# GD32W515Px register map
File version: 1.0
CPU: CM33 r0p0, little endian, MPU, FPU, 4 interrupt priority bits
Registers are 32-bit, read-write, reset 0x0 unless marked. A register's access mark holds for its fields unless they carry their own. Offsets are from the block's base; [hi:lo] are bit positions; {n}, {i} and the like mark numbered series.

## ICACHE
Base 0x40080000
Same registers: SEC_ICACHE 0x50080000
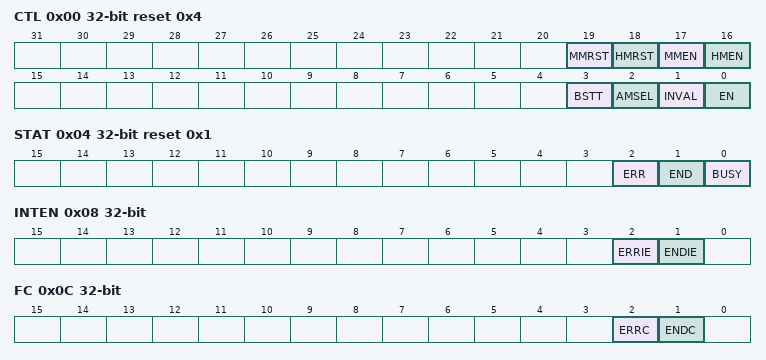
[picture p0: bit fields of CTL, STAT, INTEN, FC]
0x00 CTL reset 0x4 — Control register
  [19] MMRST — Miss monitor reset
  [18] HMRST — Hit monitor reset
  [17] MMEN — Miss monitor enable
  [16] HMEN — Hit monitor enable
  [3] BSTT — Burst type for fast bus
  [2] AMSEL — Cache set-associativity mode selection
  [1] INVAL — Cache invalidation, Set by software and cleared by hardware
  [0] EN — cache enabled
0x04 STAT ro reset 0x1 — Status register
  [2] ERR — Cache error flag
  [1] END — operation end flag
  [0] BUSY — Busy flag
0x08 INTEN — Interrupt enable register
  [2] ERRIE — cache error interrupt enable
  [1] ENDIE — cache operation end interrupt enable
0x0C FC wo — Flag clear register
  [2] ERRC — Software clear cache error flag
  [1] ENDC — Software clear operation end flag
0x10 HMC ro — Hit monitor counter register
  [31:0] HMC — Cache hit monitor counter
0x14 MMC ro — Miss monitor counter register
  [15:0] MMC — Cache miss monitor counter
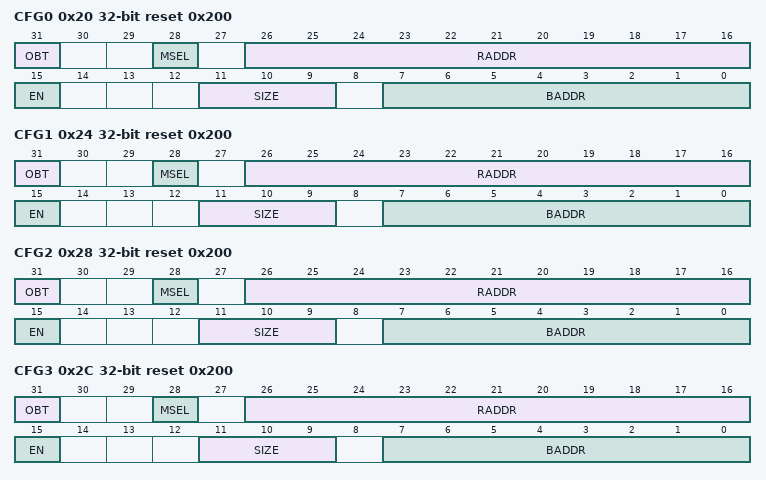
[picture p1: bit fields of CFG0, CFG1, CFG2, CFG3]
0x20 CFG0 reset 0x200 — Configuration register 0
  [31] OBT — Output burst type for region 0
  [28] MSEL — Region 0 AHB cache master selection
  [26:16] RADDR — Region 0 remapped address, this field replaces the alias address defined by BADDR field.
  [15] EN — Region 0 enable
  [11:9] SIZE — Region 0 size
  [7:0] BADDR — Region 0 base address
0x24 CFG1 reset 0x200 — Configuration register 1
  [31] OBT — Output burst type for region 1
  [28] MSEL — Region 1 AHB cache master selection
  [26:16] RADDR — Region 1 remapped address, this field replaces the alias address defined by BADDR field.
  [15] EN — Region 1 enable
  [11:9] SIZE — Region 1 size
  [7:0] BADDR — Region 1 base address
0x28 CFG2 reset 0x200 — Configuration register
  [31] OBT — Output burst type for region 2
  [28] MSEL — Region 2 AHB cache master selection
  [26:16] RADDR — Region 2 remapped address, this field replaces the alias address defined by BADDR field.
  [15] EN — Region 2 enable
  [11:9] SIZE — Region 2 size
  [7:0] BADDR — Region 2 base address
0x2C CFG3 reset 0x200 — Configuration register
  [31] OBT — Output burst type for region 3
  [28] MSEL — Region 3 AHB cache master selection
  [26:16] RADDR — Region 3 remapped address, this field replaces the alias address defined by BADDR field.
  [15] EN — Region 3 enable
  [11:9] SIZE — Region 3 size
  [7:0] BADDR — Region 3 base address

## PMU — Power management unit
Base 0x40007000
Same registers: SEC_PMU 0x50007000
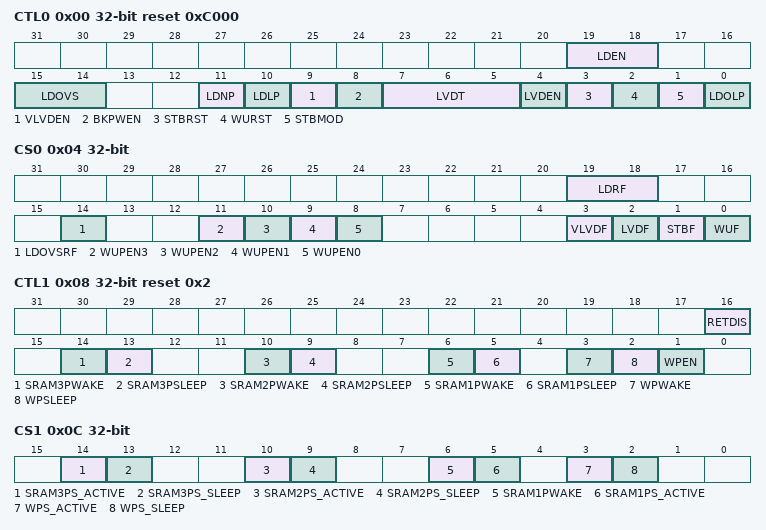
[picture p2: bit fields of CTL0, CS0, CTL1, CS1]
0x00 CTL0 reset 0xC000 — power control register 0
  [19:18] LDEN — Low-driver mode enable in Deep-sleep mode
  [15:14] LDOVS — LDO output voltage select
  [11] LDNP — Low-driver mode when use normal power LDO
  [10] LDLP — Low-driver mode when use low power LDO
  [9] VLVDEN — VDDA low voltage detect enable
  [8] BKPWEN — Backup Domain Write Enable
  [7:5] LVDT — Low Voltage Detector Threshold
  [4] LVDEN — Low Voltage Detector Enable
  [3] STBRST — Standby Flag Reset
  [2] WURST — Wakeup Flag Reset
  [1] STBMOD — Standby Mode
  [0] LDOLP — LDO Low Power Mode
0x04 CS0 access per field — power control/status register 0
  [19:18] LDRF rw — Low-driver mode ready flag
  [14] LDOVSRF ro — LDO voltage select ready flag
  [11] WUPEN3 rw — WKUP Pin3(PA12) Enable
  [10] WUPEN2 rw — WKUP Pin2(PB2) Enable
  [9] WUPEN1 rw — WKUP Pin1(PA15) Enable
  [8] WUPEN0 rw — WKUP Pin0(PA2) Enable
  [3] VLVDF ro — VDDA Low Voltage Detector Status Flag
  [2] LVDF ro — Low Voltage Detector Status Flag
  [1] STBF ro — Standby flag
  [0] WUF ro — Wakeup flag
0x08 CTL1 reset 0x2 — Control register 1
  [16] RETDIS — No retention register when WIFI por-off
  [14] SRAM3PWAKE — SRAM3 wakeup by software
  [13] SRAM3PSLEEP — SRAM3 go to sleep by software
  [10] SRAM2PWAKE — SRAM2 wakeup by software
  [9] SRAM2PSLEEP — SRAM2 go to sleep by software
  [6] SRAM1PWAKE — SRAM1 wakeup by software
  [5] SRAM1PSLEEP — SRAM1 go to sleep by software
  [3] WPWAKE — WIFI wakeup
  [2] WPSLEEP — WIFI go to sleep by software only when WPEN bit is 1
  [1] WPEN — WIFI power enable
0x0C CS1 ro — Control and status register 1
  [14] SRAM3PS_ACTIVE — SRAM3 is in active state
  [13] SRAM3PS_SLEEP — SRAM3 is in sleep state
  [10] SRAM2PS_ACTIVE — SRAM2 is in active state
  [9] SRAM2PS_SLEEP — SRAM2 is in sleep state
  [6] SRAM1PWAKE — SRAM1 wakeup by software
  [5] SRAM1PS_ACTIVE — SRAM1 is in active state
  [3] WPS_ACTIVE — WIFI is in active state
  [2] WPS_SLEEP — WIFI is in sleep state
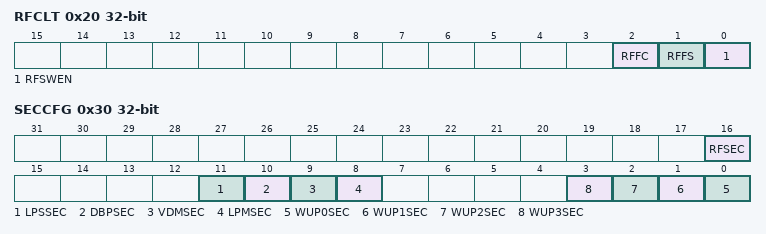
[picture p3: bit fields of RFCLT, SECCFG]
0x20 RFCLT — RF Control register
  [2] RFFC
  [1] RFFS
  [0] RFSWEN — RF sequence configured
0x30 SECCFG — Secure configuration register
  [16] RFSEC — RF security
  [11] LPSSEC — WIFI_sleep and SRAM_sleep mode security
  [10] DBPSEC — Backup Domain write access security
  [9] VDMSEC — Voltage detection and monitoring security
  [8] LPMSEC — Low-power mode security
  [n] WUP{n}SEC (n=0..3) — WKUP pin {n} security
0x34 PRICFG — Privilege configuration register
  [0] PRIV — PMU privileged access
